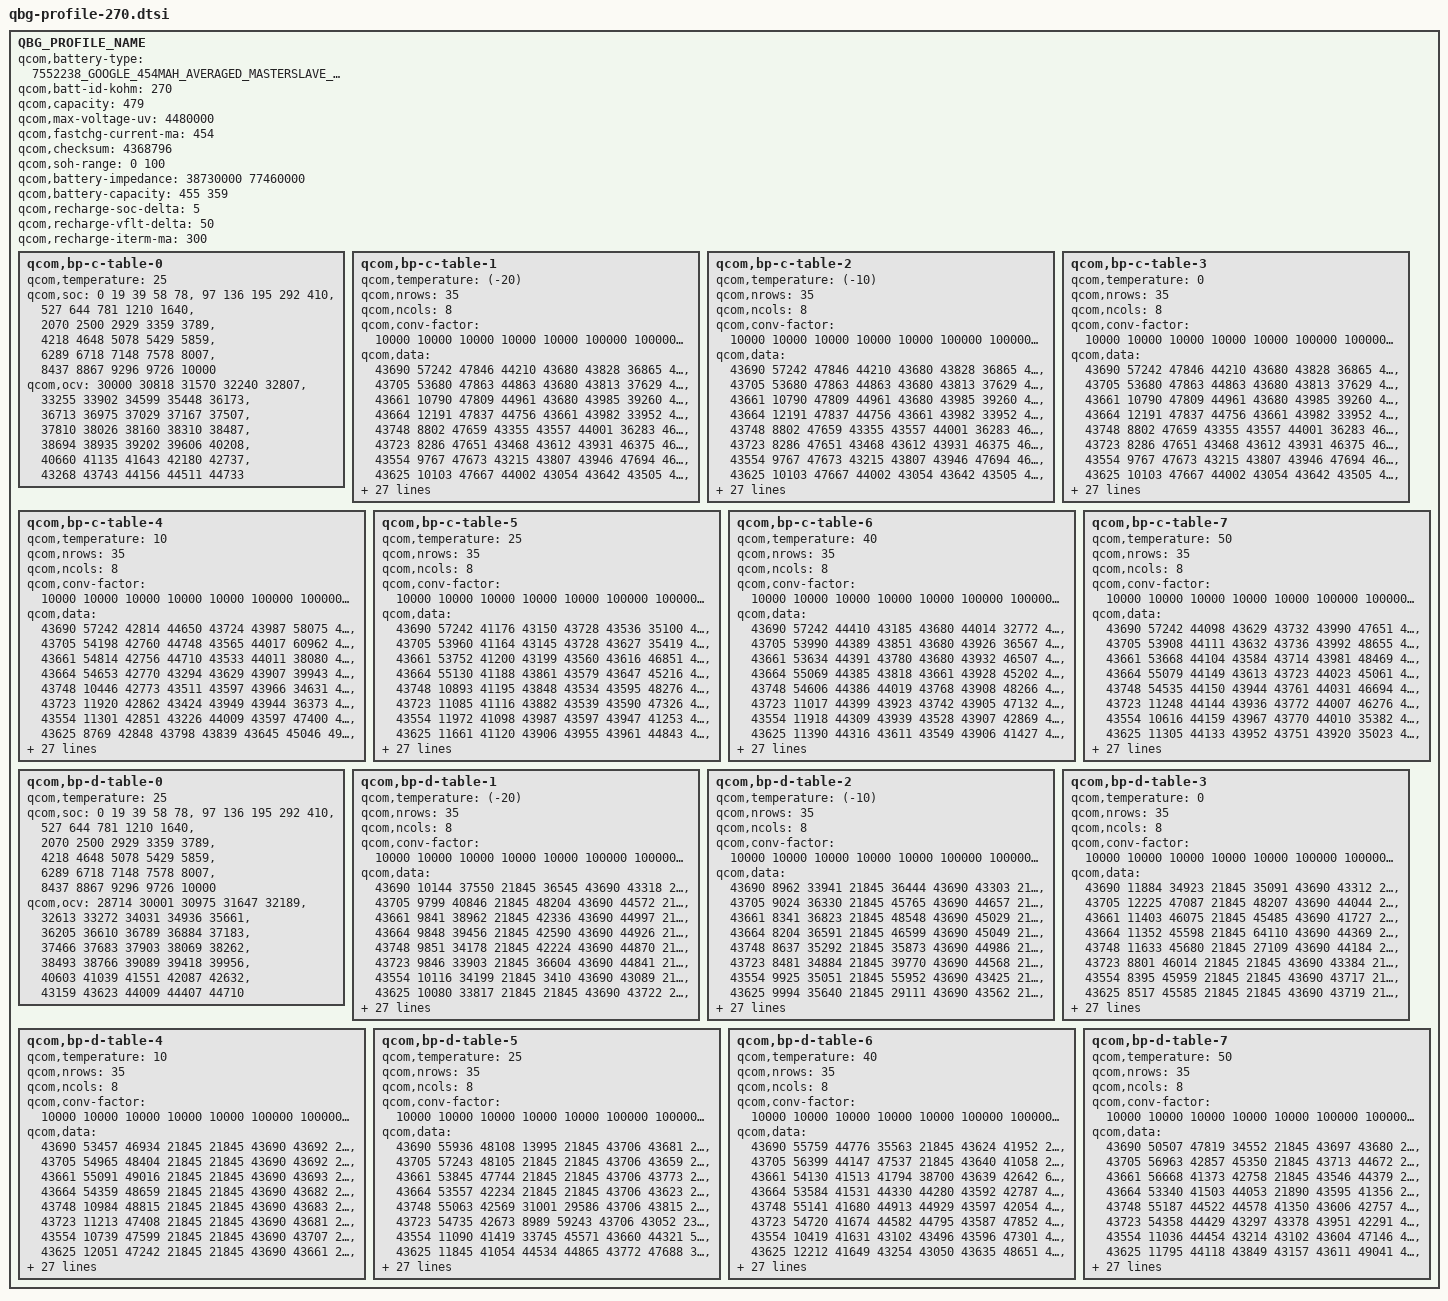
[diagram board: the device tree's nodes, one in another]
/*QBG Profiling Rev. 2.8*/

QBG_PROFILE_NAME {
	qcom,battery-type = "7552238_GOOGLE_454MAH_AVERAGED_MASTERSLAVE_DEC4TH2024";
	qcom,batt-id-kohm = <270>;
	qcom,capacity = <479>;
	qcom,max-voltage-uv = <4480000>;
	qcom,fastchg-current-ma = <454>;
	qcom,checksum = <4368796>; /*@5, 0.005V, 4% */
	qcom,soh-range = <0 100>;
	qcom,battery-impedance = <38730000 77460000>; /*Nominal_Impedance in 10nohm @ SOC 50% 25C* 0:fresh cell, 1: aged cell*/
	qcom,battery-capacity = <455 359>; /*Nominal_Capacity in mAh. 0: fresh cell, 1:aged cell*/
	qcom,recharge-soc-delta =<5>; /*SOC delta (in percent) dropped from EOC SOC to enable recharge*/
	qcom,recharge-vflt-delta =<50>; /*vfloat delta (in mV) dropped from regular vfloat in recharge*/
	qcom,recharge-iterm-ma = <300>; /*termination current (in mA) in recharge*/

	qcom,bp-c-table-0 {
		qcom,temperature = <25>;
		qcom,soc = <    0    19    39    58    78>,
			<   97   136   195   292   410>,
			<  527   644   781  1210  1640>,
			< 2070  2500  2929  3359  3789>,
			< 4218  4648  5078  5429  5859>,
			< 6289  6718  7148  7578  8007>,
			< 8437  8867  9296  9726 10000>;
		qcom,ocv = <30000 30818 31570 32240 32807>,
			<33255 33902 34599 35448 36173>,
			<36713 36975 37029 37167 37507>,
			<37810 38026 38160 38310 38487>,
			<38694 38935 39202 39606 40208>,
			<40660 41135 41643 42180 42737>,
			<43268 43743 44156 44511 44733>;
	};
	qcom,bp-c-table-1 {
		qcom,temperature = <(-20)>;
		qcom,nrows = <35>;
		qcom,ncols = <8>;
		qcom,conv-factor = <10000 10000 10000 10000 10000 100000 100000 10000>;
		qcom,data = <43690 57242 47846 44210 43680 43828 36865 47100>,
			<43705 53680 47863 44863 43680 43813 37629 46988>,
			<43661 10790 47809 44961 43680 43985 39260 46684>,
			<43664 12191 47837 44756 43661 43982 33952 46700>,
			<43748  8802 47659 43355 43557 44001 36283 46642>,
			<43723  8286 47651 43468 43612 43931 46375 46784>,
			<43554  9767 47673 43215 43807 43946 47694 46781>,
			<43625 10103 47667 44002 43054 43642 43505 45337>,
			<43918  9476 47657 43726 43453 43540 43886 45563>,
			<43824 14889 47812 43762 43432 43618 43878 45138>,
			<43173 14954 47815 43766 43394 43616 43881 45139>,
			<43054 14918 47660 43743 43430 43641 43178 45122>,
			<43431 15240 47831 43597 43066 43602 43110 45170>,
			<44560 14566 47626 43182 43247 43946 44453 45359>,
			<44226 14814 47637 44196 43905 43639 46445 46258>,
			<41660 16070 47730 44452 43971 43621 46276 46152>,
			<41838 15965 47814 44309 43803 43642 46177 46486>,
			<41435 16372 47665 41646 43842 43643 46567 46388>,
			<42933 16254 47627 41711 43189 43620 46561 35480>,
			<42087 15552 47621 41530 43258 43628 35538 35404>,
			<47824 15760 47737 41548 43255 43626 35776 35636>,
			<47234 13007 48045 41910 43257 43539 46560 35055>,
			<47484 13123 48017 41888 43209 43546 48020 34923>,
			<49055 12727 48093 41554 43074 43522 41025 35072>,
			<48201 13825 47992 41867 43327 43573 44404 36841>,
			<45627 13558 47349 41959 44773 43570 44184 36247>,
			<45204  2689 47546 41921 44946 43582 44970 33752>,
			<45382  2211 47395 41838 44178 43576 44588 34475>,
			<46896  3752 48804 41129 44393 43576 43359 34246>,
			<46573  3239 48858 41119 41150 43583 43469 40618>,
			<35423   700 48763 41071 43007 43570 43426 37065>,
			<34825   853 49099 41354 47306 43571 43036 59779>,
			<36602   276 49000 41086 45895 43580 43235 58535>,
			<36692  2041 49011 44445 46359 43735 43820 65484>,
			<36282  1183 48312 43774 45840 43758 43522 59155>;
	};
	qcom,bp-c-table-2 {
		qcom,temperature = <(-10)>;
		qcom,nrows = <35>;
		qcom,ncols = <8>;
		qcom,conv-factor = <10000 10000 10000 10000 10000 100000 100000 10000>;
		qcom,data = <43690 57242 47846 44210 43680 43828 36865 47100>,
			<43705 53680 47863 44863 43680 43813 37629 46988>,
			<43661 10790 47809 44961 43680 43985 39260 46684>,
			<43664 12191 47837 44756 43661 43982 33952 46700>,
			<43748  8802 47659 43355 43557 44001 36283 46642>,
			<43723  8286 47651 43468 43612 43931 46375 46784>,
			<43554  9767 47673 43215 43807 43946 47694 46781>,
			<43625 10103 47667 44002 43054 43642 43505 45337>,
			<43918  9476 47657 43726 43453 43540 43886 45563>,
			<43824 14889 47812 43762 43432 43618 43878 45138>,
			<43173 14954 47815 43766 43394 43616 43881 45139>,
			<43054 14918 47660 43743 43430 43641 43178 45122>,
			<43431 15240 47831 43597 43066 43602 43110 45170>,
			<44560 14566 47626 43182 43247 43946 44453 45359>,
			<44226 14814 47637 44196 43905 43639 46445 46258>,
			<41660 16070 47730 44452 43971 43621 46276 46152>,
			<41838 15965 47814 44309 43803 43642 46177 46486>,
			<41435 16372 47665 41646 43842 43643 46567 46388>,
			<42933 16254 47627 41711 43189 43620 46561 35480>,
			<42087 15552 47621 41530 43258 43628 35538 35404>,
			<47824 15760 47737 41548 43255 43626 35776 35636>,
			<47234 13007 48045 41910 43257 43539 46560 35055>,
			<47484 13123 48017 41888 43209 43546 48020 34923>,
			<49055 12727 48093 41554 43074 43522 41025 35072>,
			<48201 13825 47992 41867 43327 43573 44404 36841>,
			<45627 13558 47349 41959 44773 43570 44184 36247>,
			<45204  2689 47546 41921 44946 43582 44970 33752>,
			<45382  2211 47395 41838 44178 43576 44588 34475>,
			<46896  3752 48804 41129 44393 43576 43359 34246>,
			<46573  3239 48858 41119 41150 43583 43469 40618>,
			<35423   700 48763 41071 43007 43570 43426 37065>,
			<34825   853 49099 41354 47306 43571 43036 59779>,
			<36602   276 49000 41086 45895 43580 43235 58535>,
			<36692  2041 49011 44445 46359 43735 43820 65484>,
			<36282  1183 48312 43774 45840 43758 43522 59155>;
	};
	qcom,bp-c-table-3 {
		qcom,temperature = <0>;
		qcom,nrows = <35>;
		qcom,ncols = <8>;
		qcom,conv-factor = <10000 10000 10000 10000 10000 100000 100000 10000>;
		qcom,data = <43690 57242 47846 44210 43680 43828 36865 47100>,
			<43705 53680 47863 44863 43680 43813 37629 46988>,
			<43661 10790 47809 44961 43680 43985 39260 46684>,
			<43664 12191 47837 44756 43661 43982 33952 46700>,
			<43748  8802 47659 43355 43557 44001 36283 46642>,
			<43723  8286 47651 43468 43612 43931 46375 46784>,
			<43554  9767 47673 43215 43807 43946 47694 46781>,
			<43625 10103 47667 44002 43054 43642 43505 45337>,
			<43918  9476 47657 43726 43453 43540 43886 45563>,
			<43824 14889 47812 43762 43432 43618 43878 45138>,
			<43173 14954 47815 43766 43394 43616 43881 45139>,
			<43054 14918 47660 43743 43430 43641 43178 45122>,
			<43431 15240 47831 43597 43066 43602 43110 45170>,
			<44560 14566 47626 43182 43247 43946 44453 45359>,
			<44226 14814 47637 44196 43905 43639 46445 46258>,
			<41660 16070 47730 44452 43971 43621 46276 46152>,
			<41838 15965 47814 44309 43803 43642 46177 46486>,
			<41435 16372 47665 41646 43842 43643 46567 46388>,
			<42933 16254 47627 41711 43189 43620 46561 35480>,
			<42087 15552 47621 41530 43258 43628 35538 35404>,
			<47824 15760 47737 41548 43255 43626 35776 35636>,
			<47234 13007 48045 41910 43257 43539 46560 35055>,
			<47484 13123 48017 41888 43209 43546 48020 34923>,
			<49055 12727 48093 41554 43074 43522 41025 35072>,
			<48201 13825 47992 41867 43327 43573 44404 36841>,
			<45627 13558 47349 41959 44773 43570 44184 36247>,
			<45204  2689 47546 41921 44946 43582 44970 33752>,
			<45382  2211 47395 41838 44178 43576 44588 34475>,
			<46896  3752 48804 41129 44393 43576 43359 34246>,
			<46573  3239 48858 41119 41150 43583 43469 40618>,
			<35423   700 48763 41071 43007 43570 43426 37065>,
			<34825   853 49099 41354 47306 43571 43036 59779>,
			<36602   276 49000 41086 45895 43580 43235 58535>,
			<36692  2041 49011 44445 46359 43735 43820 65484>,
			<36282  1183 48312 43774 45840 43758 43522 59155>;
	};
	qcom,bp-c-table-4 {
		qcom,temperature = <10>;
		qcom,nrows = <35>;
		qcom,ncols = <8>;
		qcom,conv-factor = <10000 10000 10000 10000 10000 100000 100000 10000>;
		qcom,data = <43690 57242 42814 44650 43724 43987 58075 48401>,
			<43705 54198 42760 44748 43565 44017 60962 48580>,
			<43661 54814 42756 44710 43533 44011 38080 48522>,
			<43664 54653 42770 43294 43629 43907 39943 48248>,
			<43748 10446 42773 43511 43597 43966 34631 48175>,
			<43723 11920 42862 43424 43949 43944 36373 48272>,
			<43554 11301 42851 43226 44009 43597 47400 48921>,
			<43625  8769 42848 43798 43839 43645 45046 49073>,
			<43918  8523 42802 43944 43169 43607 43109 48696>,
			<43824  9413 42764 43584 43859 43915 43122 48792>,
			<43173 14987 42811 43524 43182 44008 43052 47480>,
			<43054 14857 42948 43582 43164 44000 43197 47388>,
			<43431 14948 42992 43633 43183 43932 43010 47365>,
			<44560 15143 42998 43489 43592 43613 48295 48739>,
			<44226 14448 42895 44593 43606 43647 35664 48907>,
			<41660 14682 42587 44967 43918 43622 34907 49002>,
			<41838 15892 42607 45050 43920 43618 46317 48995>,
			<41435 16261 42497 45004 44029 43618 47093 48999>,
			<42933 16133 42554 45006 43998 43618 45232 48914>,
			<42087 15584 42707 45022 43836 43629 45309 49006>,
			<47824 15789 42707 44837 43782 43618 46322 48972>,
			<47234 15695 42713 44817 43800 43617 34058 48300>,
			<47484 13253 42716 44896 43999 43618 34651 49020>,
			<49055 12680 42541 44902 43925 43541 46766 48898>,
			<48201 13890 42498 44875 43812 43550 42157 48367>,
			<45627 13319 42604 44267 43878 43521 41261 48512>,
			<45204  2601 42583 44087 43137 43528 41785 45823>,
			<45382  2256 42953 44460 43059 43575 41725 45833>,
			<46896  3622 42755 44436 43517 43569 44047 45541>,
			<46573  3075 42847 44299 44747 43568 44827 46863>,
			<35423   528 42228 44360 44884 43574 44630 35451>,
			<34825     8 42009 44410 41563 43529 43350 36788>,
			<36602  1761 42060 44424 42170 43521 43452 33273>,
			<36692  1900 42050 44894 47903 43912 43042 39620>,
			<36282  1059 42368 43038 42409 43556 43933 34328>;
	};
	qcom,bp-c-table-5 {
		qcom,temperature = <25>;
		qcom,nrows = <35>;
		qcom,ncols = <8>;
		qcom,conv-factor = <10000 10000 10000 10000 10000 100000 100000 10000>;
		qcom,data = <43690 57242 41176 43150 43728 43536 35100 42292>,
			<43705 53960 41164 43145 43728 43627 35419 42451>,
			<43661 53752 41200 43199 43560 43616 46851 42495>,
			<43664 55130 41188 43861 43579 43647 45216 42395>,
			<43748 10893 41195 43848 43534 43595 48276 42405>,
			<43723 11085 41116 43882 43539 43590 47326 42055>,
			<43554 11972 41098 43987 43597 43947 41253 41989>,
			<43625 11661 41120 43906 43955 43961 44843 42191>,
			<43918  8402 41821 43543 43971 43954 43506 42171>,
			<43824 10215 41794 43563 43824 43964 43055 42879>,
			<43173  9667 41840 43943 43604 43908 44240 42758>,
			<43054 15045 41831 43911 43625 43931 44320 42975>,
			<43431 14863 41838 43603 43936 43964 44998 42969>,
			<44560 15237 41755 43248 43640 43585 48705 42203>,
			<44226 14377 41776 43082 43944 43635 48615 42050>,
			<41660 14616 41940 43455 43966 43644 46041 42073>,
			<41838 15904 41970 43411 43942 43641 47097 42100>,
			<41435 16314 41960 43497 43941 43647 46245 42083>,
			<42933 16140 41859 43410 43918 43646 48326 42010>,
			<42087 15613 41917 43448 43995 43642 42189 42091>,
			<47824 15756 41891 43437 43781 43629 42945 42099>,
			<47234 12989 41559 43400 43874 43630 47739 42071>,
			<47484 13192 41541 43462 43796 43623 34833 42370>,
			<49055 12316 41542 43504 43977 43623 46335 42006>,
			<48201 14266 41542 43400 43940 43628 42860 42114>,
			<45627 13438 41542 43403 43928 43540 41183 42234>,
			<45204  2565 41542 43468 44012 43538 41823 42014>,
			<45382  2049 41890 43390 43821 43521 41897 42300>,
			<46896  3694 41864 44730 43895 43520 44414 47818>,
			<46573  3163 41979 44794 43202 43527 44112 47918>,
			<35423   942 41779 44736 43495 43545 44913 47199>,
			<34825   117 41751 44766 44572 43627 44965 48730>,
			<36602  1750 41816 44780 44370 43642 44723 45575>,
			<36692  1909 41144 43442 44345 43624 43376 45707>,
			<36282  1047 41806 43985 41496 43621 44020 45813>;
	};
	qcom,bp-c-table-6 {
		qcom,temperature = <40>;
		qcom,nrows = <35>;
		qcom,ncols = <8>;
		qcom,conv-factor = <10000 10000 10000 10000 10000 100000 100000 10000>;
		qcom,data = <43690 57242 44410 43185 43680 44014 32772 41127>,
			<43705 53990 44389 43851 43680 43926 36567 41144>,
			<43661 53634 44391 43780 43680 43932 46507 41148>,
			<43664 55069 44385 43818 43661 43928 45202 41149>,
			<43748 54606 44386 44019 43768 43908 48266 41138>,
			<43723 11017 44399 43923 43742 43905 47132 41148>,
			<43554 11918 44309 43939 43528 43907 42869 41147>,
			<43625 11390 44316 43611 43549 43906 41427 41129>,
			<43918  8373 44301 43906 43713 43921 47893 41841>,
			<43824  9822 44340 43938 43559 44001 41245 41828>,
			<43173  9658 44348 43946 43554 44029 41278 41758>,
			<43054 15082 44324 43587 43743 44005 42723 41941>,
			<43431 15069 44332 43945 43767 44002 48712 41938>,
			<44560 14916 44496 43970 43634 43963 42641 41207>,
			<44226 14480 44493 43784 43615 43605 42873 40969>,
			<41660 14836 44537 43875 43612 43602 47468 40985>,
			<41838 16019 44521 43890 43639 43611 46064 40968>,
			<41435 15951 44440 43879 43620 43610 48761 41180>,
			<42933 16166 44469 43851 43641 43610 47344 41175>,
			<42087 15585 44452 43787 44007 43601 41509 40974>,
			<47824 15747 44457 43974 43792 43612 44132 41060>,
			<47234 12941 44112 43815 43884 43586 41923 41052>,
			<47484 13281 44126 43901 43791 43599 47601 41381>,
			<49055 12376 44122 43878 43918 43586 47655 41020>,
			<48201 14256 44103 43807 43633 43587 41041 41090>,
			<45627 13385 44102 43799 43595 43599 41761 41117>,
			<45204  2664 44100 43855 43613 43632 41587 41000>,
			<45382  2156 44120 43174 43914 43621 44333 41034>,
			<46896  3663 44113 43250 44023 43627 44060 41258>,
			<46573  3500 44449 43032 43830 43541 44526 42650>,
			<35423   958 44428 43116 43137 43618 44166 42564>,
			<34825    66 44521 43074 43083 43637 44894 42819>,
			<36602  1582 44492 43036 44576 43600 44667 42457>,
			<36692  1866 44344 43850 43334 43586 44671 42214>,
			<36282  1150 44510 43818 44822 43924 43188 42271>;
	};
	qcom,bp-c-table-7 {
		qcom,temperature = <50>;
		qcom,nrows = <35>;
		qcom,ncols = <8>;
		qcom,conv-factor = <10000 10000 10000 10000 10000 100000 100000 10000>;
		qcom,data = <43690 57242 44098 43629 43732 43990 47651 41686>,
			<43705 53908 44111 43632 43736 43992 48655 41505>,
			<43661 53668 44104 43584 43714 43981 48469 41533>,
			<43664 55079 44149 43613 43723 44023 45061 41482>,
			<43748 54535 44150 43944 43761 44031 46694 41474>,
			<43723 11248 44144 43936 43772 44007 46276 41476>,
			<43554 10616 44159 43967 43770 44010 35382 41503>,
			<43625 11305 44133 43952 43751 43920 35023 41490>,
			<43918  9083 44141 43944 43772 44002 45493 41521>,
			<43824  9730 44053 43599 43724 44022 42838 41513>,
			<43173  9324 44051 43537 43565 43822 41545 41690>,
			<43054 15010 44063 43521 43725 43818 42699 41631>,
			<43431 15084 44037 43543 43775 43969 47355 41624>,
			<44560 14875 44034 43946 43634 44010 41949 41896>,
			<44226 15190 44086 43914 43588 43928 41140 41881>,
			<41660 14730 44088 43928 43608 43911 42945 41962>,
			<41838 16044 44077 43934 43597 43916 47805 41857>,
			<41435 15980 44241 43921 43548 43959 48079 41559>,
			<42933 16336 44229 44025 43547 43964 47840 41890>,
			<42087 15511 44238 44021 43611 43919 41179 41965>,
			<47824 15759 44279 43635 43783 43932 44942 41950>,
			<47234 12934 44284 43601 43802 43959 44308 41789>,
			<47484 13302 44283 43926 43808 43962 42343 41736>,
			<49055 12716 44261 43927 43606 43966 42469 41868>,
			<48201 14262 44262 43908 43548 43954 41220 41583>,
			<45627 13389 44257 43908 43627 43960 41681 41595>,
			<45204  2656 44257 44000 43594 43944 44507 41906>,
			<45382  2170 44260 43818 43589 43609 44305 41927>,
			<46896  3652 44281 43880 43949 43599 41618 41852>,
			<46573  3515 44274 43183 43977 43645 44109 41003>,
			<35423   956 44232 43241 43801 43638 44491 41405>,
			<34825    67 44251 43153 43263 43584 44273 41237>,
			<36602  1750 44076 43138 43459 43963 44823 42604>,
			<36692  1907 44042 43818 43073 43967 44887 41247>,
			<36282  1136 44268 43853 44717 43960 43506 42614>;
	};
	qcom,bp-d-table-0 {
		qcom,temperature = <25>;
		qcom,soc = <    0    19    39    58    78>,
			<   97   136   195   292   410>,
			<  527   644   781  1210  1640>,
			< 2070  2500  2929  3359  3789>,
			< 4218  4648  5078  5429  5859>,
			< 6289  6718  7148  7578  8007>,
			< 8437  8867  9296  9726 10000>;
		qcom,ocv = <28714 30001 30975 31647 32189>,
			<32613 33272 34031 34936 35661>,
			<36205 36610 36789 36884 37183>,
			<37466 37683 37903 38069 38262>,
			<38493 38766 39089 39418 39956>,
			<40603 41039 41551 42087 42632>,
			<43159 43623 44009 44407 44710>;
	};
	qcom,bp-d-table-1 {
		qcom,temperature = <(-20)>;
		qcom,nrows = <35>;
		qcom,ncols = <8>;
		qcom,conv-factor = <10000 10000 10000 10000 10000 100000 100000 10000>;
		qcom,data = <43690 10144 37550 21845 36545 43690 43318 21845>,
			<43705  9799 40846 21845 48204 43690 44572 21845>,
			<43661  9841 38962 21845 42336 43690 44997 21845>,
			<43664  9848 39456 21845 42590 43690 44926 21845>,
			<43748  9851 34178 21845 42224 43690 44870 21845>,
			<43723  9846 33903 21845 36604 43690 44841 21845>,
			<43554 10116 34199 21845  3410 43690 43089 21845>,
			<43625 10080 33817 21845 21845 43690 43722 21845>,
			<43918  9460 34435 21845  5714 43690 43558 21845>,
			<43824  9238 33076 21845 52279 43690 43631 21845>,
			<43173  9639 32821 21845 59858 43690 43584 21845>,
			<43054  9714 33577 21845 34277 43690 43960 21845>,
			<43431  9492 33452 21845 35793 43690 43815 21845>,
			<44560 14910 36091  6015 46888 43691 43227 21845>,
			<44226 15331 36560 57093 45736 43688 43092 21845>,
			<41660 15175 35012 63546 47207 43688 43309 16890>,
			<41838 14375 35390 37129 42231 43689 44686  6071>,
			<41435 14746 46530 34332 41463 43694 44655 13916>,
			<42933 14716 46932 35206 41955 43695 44995 11476>,
			<42087 15913 47023 46747 41663 43692 44812 57202>,
			<47824 16277 46822 48426 44476 43693 44208 50138>,
			<47234 15549 45382 49145 44232 43682 44451 51506>,
			<47484 15758 45376 48642 44160 43682 41708 51344>,
			<49055 13028 46755 48880 44272 43683 41100 51994>,
			<48201 13126 45389 47436 44458 43683 40984 52016>,
			<45627 12654 46759 47365 44410 43680 41444 52047>,
			<45204 14149 46726 47426 41598 43681 42612 51642>,
			<45382  2689 46756 48860 41837 43686 42969 52955>,
			<46896  2194 45336 48760 41202 43687 41307 53236>,
			<46573  3617 45364 48999 41062 43706 42791 52631>,
			<35423  3183 45332 49077 41353 43756 42204 50110>,
			<34825   530 45511 48949 41400 43753 42662 50038>,
			<36602     8 45537 48421 41120 43650 41870 49941>,
			<36692  1627 45539 45533 44491 43690 44226 49781>,
			<36282  1134 45555 46852 44233 43690 44649 52568>;
	};
	qcom,bp-d-table-2 {
		qcom,temperature = <(-10)>;
		qcom,nrows = <35>;
		qcom,ncols = <8>;
		qcom,conv-factor = <10000 10000 10000 10000 10000 100000 100000 10000>;
		qcom,data = <43690  8962 33941 21845 36444 43690 43303 21845>,
			<43705  9024 36330 21845 45765 43690 44657 21845>,
			<43661  8341 36823 21845 48548 43690 45029 21845>,
			<43664  8204 36591 21845 46599 43690 45049 21845>,
			<43748  8637 35292 21845 35873 43690 44986 21845>,
			<43723  8481 34884 21845 39770 43690 44568 21845>,
			<43554  9925 35051 21845 55952 43690 43425 21845>,
			<43625  9994 35640 21845 29111 43690 43562 21845>,
			<43918  9424 35421 21845 50367 43690 43625 21845>,
			<43824  9650 46457 21845 34157 43690 44024 21845>,
			<43173  9518 46204 21845 45062 43690 43855 21845>,
			<43054  9586 46927 27250 48020 43691 43049 21845>,
			<43431 14980 46828 52676 41277 43691 43463 21845>,
			<44560 14933 45905 33277 41489 43688 44946 13116>,
			<44226 15165 48597 45121 44130 43694 44278 51106>,
			<41660 14467 48369 48778 45012 43692 44109 62432>,
			<41838 14441 48331 48076 44936 43682 44152 63606>,
			<41435 14794 48152 42048 44968 43683 44231 58519>,
			<42933 16047 48236 42998 44641 43681 44076 57412>,
			<42087 15980 48236 42554 44749 43684 44305 57919>,
			<47824 16149 48249 42674 44781 43704 41147 60916>,
			<47234 15786 48242 41277 44569 43700 42680 60858>,
			<47484 13016 48242 41059 44631 43764 42009 60854>,
			<49055 13076 48555 41006 44979 43572 47829 60903>,
			<48201 12583 48568 41031 44861 43527 47929 60771>,
			<45627 14138 48217 41270 44242 43521 47623 57915>,
			<45204 13595 48243 42538 44469 43529 42348 58126>,
			<45382  2890 48243 42762 44335 43568 47806 57410>,
			<46896  3771 48156 42177 41654 43558 42401 59069>,
			<46573  3225 48128 42399 41525 43561 42171 59389>,
			<35423   654 48332 42316 41561 43729 42585 58410>,
			<34825   867 48367 47649 41498 43739 41400 58785>,
			<36602   486 48366 47724 44490 43722 41961 58441>,
			<36692  1924 48323 47719 44601 43756 44387 59202>,
			<36282  1123 48164 47616 43424 43678 44454 58962>;
	};
	qcom,bp-d-table-3 {
		qcom,temperature = <0>;
		qcom,nrows = <35>;
		qcom,ncols = <8>;
		qcom,conv-factor = <10000 10000 10000 10000 10000 100000 100000 10000>;
		qcom,data = <43690 11884 34923 21845 35091 43690 43312 21845>,
			<43705 12225 47087 21845 48207 43690 44044 21845>,
			<43661 11403 46075 21845 45485 43690 41727 21845>,
			<43664 11352 45598 21845 64110 43690 44369 21845>,
			<43748 11633 45680 21845 27109 43690 44184 21845>,
			<43723  8801 46014 21845 21845 43690 43384 21845>,
			<43554  8395 45959 21845 21845 43690 43717 21845>,
			<43625  8517 45585 21845 21845 43690 43719 21845>,
			<43918 10015 48393 21845 59570 43690 43614 21845>,
			<43824  9329 48375 21845 45971 43690 43886 21845>,
			<43173  9673 49109 13335 41293 43690 43078 21845>,
			<43054  9477 48731 58294 44110 43691 44675 25353>,
			<43431  9561 48817 34898 44616 43688 44637  8792>,
			<44560 14867 47525 41305 43468 43692 44073 58930>,
			<44226 15317 47317 42504 43420 43682 41098 60976>,
			<41660 14566 47233 41175 43517 43684 41342 38787>,
			<41838 14757 47263 41636 43432 43739 47969 37585>,
			<41435 14607 47238 44117 43032 43573 48110 40516>,
			<42933 16105 47239 44104 43062 43533 47847 38920>,
			<42087 16257 47299 44116 43012 43546 48817 39733>,
			<47824 15584 47161 44455 43501 43551 48705 39815>,
			<47234 15811 47328 44455 43277 43539 47756 39433>,
			<47484 12822 47303 44532 43353 43537 42040 39460>,
			<49055 13139 47346 44395 44678 43538 42846 39472>,
			<48201 12642 47346 41676 44572 43547 42877 39859>,
			<45627 14207 47309 41860 45046 43523 42794 39054>,
			<45204 13652 47305 41122 44875 43573 42617 39315>,
			<45382  2193 47336 41081 44225 43577 42558 40668>,
			<46896  3828 47232 41453 44129 43554 41086 40930>,
			<46573  3293 47243 41323 44453 43562 41811 40084>,
			<35423   706 47264 42642 44426 43728 41743 40383>,
			<34825   191 47948 42559 44149 43742 41963 40384>,
			<36602   295 47946 42542 44902 43715 41897 40331>,
			<36692  2022 47276 41295 43327 43772 41591 40781>,
			<36282  1134 47253 41451 43235 43744 41541 40839>;
	};
	qcom,bp-d-table-4 {
		qcom,temperature = <10>;
		qcom,nrows = <35>;
		qcom,ncols = <8>;
		qcom,conv-factor = <10000 10000 10000 10000 10000 100000 100000 10000>;
		qcom,data = <43690 53457 46934 21845 21845 43690 43692 21845>,
			<43705 54965 48404 21845 21845 43690 43692 21845>,
			<43661 55091 49016 21845 21845 43690 43693 21845>,
			<43664 54359 48659 21845 21845 43690 43682 21845>,
			<43748 10984 48815 21845 21845 43690 43683 21845>,
			<43723 11213 47408 21845 21845 43690 43681 21845>,
			<43554 10739 47599 21845 21845 43690 43707 21845>,
			<43625 12051 47242 21845 21845 43690 43661 21845>,
			<43918  9127 48047 21845 10047 43690 43523 21845>,
			<43824  9915 42331 32124 48852 43690 43208 21845>,
			<43173  9344 42443 61008 44495 43691 44649  6069>,
			<43054  9619 42422 46776 44779 43688 44429 56772>,
			<43431  9520 41991 41230 43124 43695 44318 57606>,
			<44560 14984 42092 44862 43798 43661 41215 33971>,
			<44226 15311 42006 45033 43237 43560 48016 33608>,
			<41660 14533 42116 44929 43113 43527 47984 36726>,
			<41838 14772 42163 44973 43031 43536 48032 34831>,
			<41435 14593 42118 44623 43253 43624 47722 35558>,
			<42933 16065 42126 44969 43261 43628 48926 46591>,
			<42087 16352 42220 44632 43015 43629 47222 46182>,
			<47824 15510 42232 44628 43109 43616 42263 46328>,
			<47234 15864 42140 44980 43127 43618 42968 46927>,
			<47484 12811 42132 45001 43088 43625 42906 46940>,
			<49055 13131 42219 44815 43395 43540 42912 46235>,
			<48201 12568 42130 44192 43327 43536 42584 46183>,
			<45627 14157 42139 44136 44770 43539 42160 35460>,
			<45204  2786 42123 44326 44636 43549 47854 35607>,
			<45382  2300 42144 44338 45001 43532 41380 35011>,
			<46896  3791 42152 44298 44844 43568 41705 34883>,
			<46573  3119 42169 41637 45021 43556 41714 35087>,
			<35423   559 42151 41694 45009 43555 41511 36401>,
			<34825   149 42837 41527 45028 43565 41575 36846>,
			<36602   276 42846 41518 44597 43562 41919 36838>,
			<36692  1996 42822 44372 43408 43712 41979 36354>,
			<36282  1040 42817 44291 43249 43767 41981 35095>;
	};
	qcom,bp-d-table-5 {
		qcom,temperature = <25>;
		qcom,nrows = <35>;
		qcom,ncols = <8>;
		qcom,conv-factor = <10000 10000 10000 10000 10000 100000 100000 10000>;
		qcom,data = <43690 55936 48108 13995 21845 43706 43681 21845>,
			<43705 57243 48105 21845 21845 43706 43659 21845>,
			<43661 53845 47744 21845 21845 43706 43773 21845>,
			<43664 53557 42234 21845 21845 43706 43623 21845>,
			<43748 55063 42569 31001 29586 43706 43815 21845>,
			<43723 54735 42673  8989 59243 43706 43052 23372>,
			<43554 11090 41419 33745 45571 43660 44321 52560>,
			<43625 11845 41054 44534 44865 43772 47688 34109>,
			<43918  8914 41079 44642 44717 43740 45805 35213>,
			<43824  8679 41059 43345 43008 43564 45335 46663>,
			<43173 10183 40978 43481 43848 43578 48299 45987>,
			<43054  9640 40980 43410 43859 43582 41421 48603>,
			<43431  9503 40965 43441 43776 43547 41262 48917>,
			<44560 15038 41019 43257 43591 43540 42765 47276>,
			<44226 15253 41199 43043 43815 43631 41453 47955>,
			<41660 14576 41140 43034 43889 43592 42946 47916>,
			<41838 14745 41811 43115 43150 43609 42022 48119>,
			<41435 16037 41809 43088 43226 43946 48814 47909>,
			<42933 15903 41845 43113 43220 43614 42996 48039>,
			<42087 16348 41827 43028 43257 43591 41376 47619>,
			<47824 15607 41758 43104 43196 43599 41085 47851>,
			<47234 15812 41752 43131 43842 43637 41079 42327>,
			<47484 12827 41742 43122 43893 43636 41379 42317>,
			<49055 13136 41782 43100 43864 43637 42672 47776>,
			<48201 14014 41777 43487 43025 43599 47689 48127>,
			<45627 13361 41786 43341 44711 43588 48808 47542>,
			<45204  2789 41761 43307 43381 43619 41888 47138>,
			<45382  2277 41788 43301 43320 43622 44479 47312>,
			<46896  3789 41781 43388 43092 43640 44498 47356>,
			<46573  3106 41756 44726 43222 43642 41488 47345>,
			<35423   573 41833 44681 43200 43617 41103 47163>,
			<34825   205 41828 43359 43059 43626 41140 47225>,
			<36602   323 41847 43292 43065 43541 41185 47221>,
			<36692  2013 41799 43301 43856 43646 41222 47126>,
			<36282  1036 41811 43296 43974 43591 42580 47318>;
	};
	qcom,bp-d-table-6 {
		qcom,temperature = <40>;
		qcom,nrows = <35>;
		qcom,ncols = <8>;
		qcom,conv-factor = <10000 10000 10000 10000 10000 100000 100000 10000>;
		qcom,data = <43690 55759 44776 35563 21845 43624 41952 21845>,
			<43705 56399 44147 47537 21845 43640 41058 21845>,
			<43661 54130 41513 41794 38700 43639 42642 63834>,
			<43664 53584 41531 44330 44280 43592 42787 45972>,
			<43748 55141 41680 44913 44929 43597 42054 48921>,
			<43723 54720 41674 44582 44795 43587 47852 47527>,
			<43554 10419 41631 43102 43496 43596 47301 42312>,
			<43625 12212 41649 43254 43050 43635 48651 42139>,
			<43918  8705 41647 43139 43163 43638 45300 42971>,
			<43824  8484 44367 43192 43242 43597 46342 42896>,
			<43173 10193 44400 43171 43992 43588 46418 42730>,
			<43054  9302 44388 43865 43938 43590 42199 41223>,
			<43431  9570 44399 43148 43943 43585 42656 41328>,
			<44560 15013 44291 44026 43583 43949 47852 41197>,
			<44226 15244 44327 43814 43964 43941 41225 41073>,
			<41660 14481 44485 43791 44014 43954 42517 41045>,
			<41838 14733 44534 43833 43794 43967 41216 41455>,
			<41435 16051 44537 43826 43236 43917 41779 41340>,
			<42933 15973 44525 43900 43864 44010 40993 41220>,
			<42087 16182 44434 43902 43886 43918 41039 41408>,
			<47824 15407 44420 43880 43820 43966 41080 41400>,
			<47234 15653 44419 43799 43931 43937 42641 40984>,
			<47484 12909 44425 43801 43959 43946 42934 40997>,
			<49055 12433 44468 43889 43999 43943 47336 41406>,
			<48201 14032 44477 43149 43104 43917 48436 42510>,
			<45627 13554 44476 43875 43494 43589 44298 42610>,
			<45204  2707 44465 43243 43054 43966 44494 42551>,
			<45382  2200 44427 43110 43808 43967 41200 42729>,
			<46896  3811 44421 43110 43907 43615 42718 41309>,
			<46573  3264 44522 43040 43956 43644 41427 41234>,
			<35423   721 44536 43261 43965 43643 42512 41274>,
			<34825   242 44486 43136 44007 43635 42551 41246>,
			<36602   374 44330 43869 44020 43597 42714 41243>,
			<36692  1993 44332 43883 43938 43603 42580 41348>,
			<36282  1063 44501 43778 43735 43950 42153 40964>;
	};
	qcom,bp-d-table-7 {
		qcom,temperature = <50>;
		qcom,nrows = <35>;
		qcom,ncols = <8>;
		qcom,conv-factor = <10000 10000 10000 10000 10000 100000 100000 10000>;
		qcom,data = <43690 50507 47819 34552 21845 43697 43680 21845>,
			<43705 56963 42857 45350 21845 43713 44672 21845>,
			<43661 56668 41373 42758 21845 43546 44379 21845>,
			<43664 53340 41503 44053 21890 43595 41356 21845>,
			<43748 55187 44522 44578 41350 43606 42757 45718>,
			<43723 54358 44429 43297 43378 43951 42291 42298>,
			<43554 11036 44454 43214 43102 43604 47146 42986>,
			<43625 11795 44118 43849 43157 43611 49041 41333>,
			<43918  8934 44096 43781 43875 43612 45187 41406>,
			<43824  8698 44146 43786 43171 43944 46361 41344>,
			<43173 10220 44128 43836 43975 43937 35726 41153>,
			<43054  9318 44137 43784 43641 43951 46049 41855>,
			<43431  9487 44052 43849 43628 43604 47866 41125>,
			<44560  9562 44038 43612 43733 43932 47512 41484>,
			<44226 15273 44081 44001 43644 43927 42486 41963>,
			<41660 14527 44065 43920 43954 44013 41246 41972>,
			<41838 14766 44075 43933 44004 44016 42535 41773>,
			<41435 16039 44246 43998 43804 43834 41369 41092>,
			<42933 15966 44254 43826 43853 43975 42552 41168>,
			<42087 16146 44228 43969 43793 44024 41948 41141>,
			<47824 15408 44229 43808 43934 44025 42690 41746>,
			<47234 15624 44225 43999 43595 43935 42001 41955>,
			<47484 12914 44237 44002 43637 43917 42132 41911>,
			<49055 12513 44238 44017 44030 43911 42479 41781>,
			<48201 13863 44235 43788 43067 43926 48007 41347>,
			<45627 13559 44235 43827 43021 43905 44520 41450>,
			<45204  2719 44235 43221 44002 44016 42636 41078>,
			<45382  2201 44236 43253 43939 43949 42750 41001>,
			<46896  3814 44231 43153 43642 43596 42288 41093>,
			<46573  3270 44252 43180 43551 43599 47270 41805>,
			<35423   722 44074 43875 43551 43584 47961 41731>,
			<34825   248 44070 43834 43591 43600 42387 41755>,
			<36602   377 44083 43978 43946 43941 42826 41736>,
			<36692  2046 44034 43926 43520 43913 42441 41880>,
			<36282  1236 44056 43911 43703 43930 47313 41548>;
	};
};
